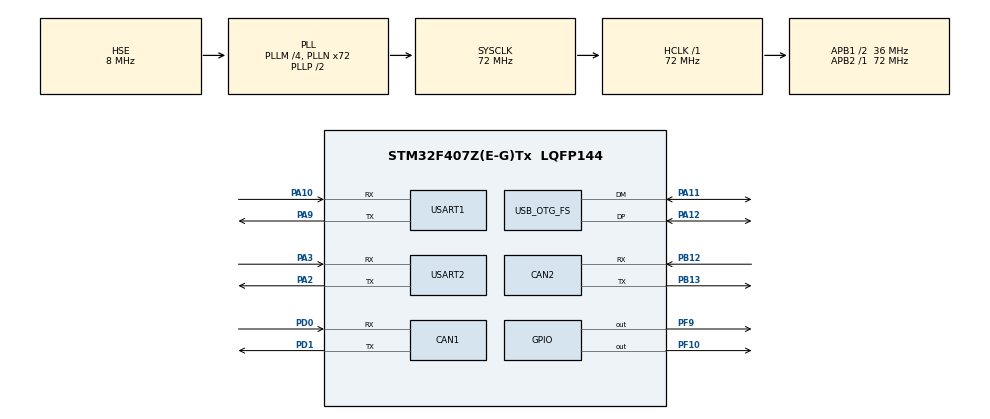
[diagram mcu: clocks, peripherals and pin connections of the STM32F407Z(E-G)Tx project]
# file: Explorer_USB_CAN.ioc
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CAN1.CalculateTimeQuantum=444.44444444444446
CAN2.CalculateTimeQuantum=444.44444444444446
FREERTOS.Tasks01=defaultTask,0,128,StartDefaultTask,Default,NULL
Mcu.Family=STM32F4
Mcu.Name=STM32F407Z(E-G)Tx
Mcu.Package=LQFP144
NVIC.CAN1_RX0_IRQn=true\:5\:0\:false\:false\:true\:true\:true\:true
NVIC.CAN1_RX1_IRQn=true\:5\:0\:false\:false\:true\:true\:true\:true
NVIC.CAN1_SCE_IRQn=true\:5\:0\:false\:false\:true\:true\:true\:true
NVIC.CAN1_TX_IRQn=true\:5\:0\:false\:false\:true\:true\:true\:true
NVIC.CAN2_RX0_IRQn=true\:5\:0\:false\:false\:true\:true\:true\:true
NVIC.CAN2_RX1_IRQn=true\:5\:0\:false\:false\:true\:true\:true\:true
NVIC.CAN2_SCE_IRQn=true\:5\:0\:false\:false\:true\:true\:true\:true
NVIC.CAN2_TX_IRQn=true\:5\:0\:false\:false\:true\:true\:true\:true
NVIC.OTG_FS_IRQn=true\:5\:0\:false\:false\:true\:true\:false\:true
NVIC.PriorityGroup=NVIC_PRIORITYGROUP_4
NVIC.USART1_IRQn=true\:5\:0\:false\:false\:true\:true\:true\:true
NVIC.USART2_IRQn=true\:5\:0\:false\:false\:true\:true\:true\:true
PA10.Mode=Asynchronous
PA10.Signal=USART1_RX
PA11.Mode=Device_Only
PA11.Signal=USB_OTG_FS_DM
PA12.Mode=Device_Only
PA12.Signal=USB_OTG_FS_DP
PA2.Mode=Asynchronous
PA2.Signal=USART2_TX
PA3.Mode=Asynchronous
PA3.Signal=USART2_RX
PA9.Mode=Asynchronous
PA9.Signal=USART1_TX
PB12.Mode=Slave
PB12.Signal=CAN2_RX
PB13.Mode=Slave
PB13.Signal=CAN2_TX
PC14-OSC32_IN.Mode=LSE-External-Oscillator
PC14-OSC32_IN.Signal=RCC_OSC32_IN
PC15-OSC32_OUT.Mode=LSE-External-Oscillator
PC15-OSC32_OUT.Signal=RCC_OSC32_OUT
PD0.Mode=Master
PD0.Signal=CAN1_RX
PD1.Mode=Master
PD1.Signal=CAN1_TX
PF10.Signal=GPIO_Output
PF9.Signal=GPIO_Output
PH0-OSC_IN.Mode=HSE-External-Oscillator
PH0-OSC_IN.Signal=RCC_OSC_IN
PH1-OSC_OUT.Mode=HSE-External-Oscillator
PH1-OSC_OUT.Signal=RCC_OSC_OUT
ProjectManager.HeapSize=0x800
ProjectManager.StackSize=0x800
ProjectManager.TargetToolchain=TrueSTUDIO
RCC.48MHZClocksFreq_Value=48000000
RCC.AHBFreq_Value=72000000
RCC.APB1CLKDivider=RCC_HCLK_DIV2
RCC.APB1Freq_Value=36000000
RCC.APB1TimFreq_Value=72000000
RCC.APB2Freq_Value=72000000
RCC.APB2TimFreq_Value=72000000
RCC.CortexFreq_Value=72000000
RCC.HCLKFreq_Value=72000000
RCC.HSE_VALUE=8000000
RCC.HSI_VALUE=16000000
RCC.PLLM=4
RCC.PLLN=72
RCC.PLLQ=3
RCC.SYSCLKFreq_VALUE=72000000
RCC.SYSCLKSource=RCC_SYSCLKSOURCE_PLLCLK
RCC.VCOOutputFreq_Value=144000000
USART1.VirtualMode=VM_ASYNC
USART2.VirtualMode=VM_ASYNC
USB_DEVICE.CLASS_NAME_FS=CDC
USB_DEVICE.VirtualMode-CDC_FS=Cdc
USB_DEVICE.VirtualModeFS=Cdc_FS
USB_OTG_FS.VirtualMode=Device_Only
VP_FREERTOS_VS_CMSIS_V1.Mode=CMSIS_V1
VP_USB_DEVICE_VS_USB_DEVICE_CDC_FS.Mode=CDC_FS
board=custom

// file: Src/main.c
/* USER CODE BEGIN Header */
/**
  ******************************************************************************
  * @file           : main.c
  * @brief          : Main program body
  ******************************************************************************
  * @attention
  *
  * <h2><center>&copy; Copyright (c) 2019 STMicroelectronics.
  * All rights reserved.</center></h2>
  *
  * This software component is licensed by ST under Ultimate Liberty license
  * SLA0044, the "License"; You may not use this file except in compliance with
  * the License. You may obtain a copy of the License at:
  *                             www.st.com/SLA0044
  *
  ******************************************************************************
  */
/* USER CODE END Header */

#include "main.h"
#include "cmsis_os.h"
#include "can.h"
#include "usart.h"
#include "usb_device.h"
#include "gpio.h"
#include <stdio.h>

void SystemClock_Config(void);
void MX_FREERTOS_Init(void);

int main(void)
{

  /* MCU Configuration--------------------------------------------------------*/

  /* Reset of all peripherals, Initializes the Flash interface and the Systick. */
  HAL_Init();

  /* Configure the system clock */
  SystemClock_Config();

  /* Initialize all configured peripherals */
  MX_GPIO_Init();
  MX_CAN1_Init();
  MX_CAN2_Init();
  MX_USART1_UART_Init();
  MX_USART2_UART_Init();
  /* USER CODE BEGIN 2 */
 printf("%s->%s->%d",__FILE__,__FUNCTION__,__LINE__);
  /* USER CODE END 2 */

  /* Call init function for freertos objects (in freertos.c) */
  MX_FREERTOS_Init();

  /* Start scheduler */
  osKernelStart();

  /* We should never get here as control is now taken by the scheduler */

  /* Infinite loop */
  while (1)
  {

  }
}

void SystemClock_Config(void)
{
  RCC_OscInitTypeDef RCC_OscInitStruct = {0};
  RCC_ClkInitTypeDef RCC_ClkInitStruct = {0};

  /** Configure the main internal regulator output voltage
  */
  __HAL_RCC_PWR_CLK_ENABLE();
  __HAL_PWR_VOLTAGESCALING_CONFIG(PWR_REGULATOR_VOLTAGE_SCALE1);
  /** Initializes the CPU, AHB and APB busses clocks
  */
  RCC_OscInitStruct.OscillatorType = RCC_OSCILLATORTYPE_HSE;
  RCC_OscInitStruct.HSEState = RCC_HSE_ON;
  RCC_OscInitStruct.PLL.PLLState = RCC_PLL_ON;
  RCC_OscInitStruct.PLL.PLLSource = RCC_PLLSOURCE_HSE;
  RCC_OscInitStruct.PLL.PLLM = 4;
  RCC_OscInitStruct.PLL.PLLN = 72;
  RCC_OscInitStruct.PLL.PLLP = RCC_PLLP_DIV2;
  RCC_OscInitStruct.PLL.PLLQ = 3;
  if (HAL_RCC_OscConfig(&RCC_OscInitStruct) != HAL_OK)
  {
    Error_Handler();
  }
  /** Initializes the CPU, AHB and APB busses clocks
  */
  RCC_ClkInitStruct.ClockType = RCC_CLOCKTYPE_HCLK|RCC_CLOCKTYPE_SYSCLK
                              |RCC_CLOCKTYPE_PCLK1|RCC_CLOCKTYPE_PCLK2;
  RCC_ClkInitStruct.SYSCLKSource = RCC_SYSCLKSOURCE_PLLCLK;
  RCC_ClkInitStruct.AHBCLKDivider = RCC_SYSCLK_DIV1;
  RCC_ClkInitStruct.APB1CLKDivider = RCC_HCLK_DIV2;
  RCC_ClkInitStruct.APB2CLKDivider = RCC_HCLK_DIV1;

  if (HAL_RCC_ClockConfig(&RCC_ClkInitStruct, FLASH_LATENCY_2) != HAL_OK)
  {
    Error_Handler();
  }
}

void Error_Handler(void)
{
}

/************************ (C) COPYRIGHT STMicroelectronics *****END OF FILE****/

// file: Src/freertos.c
/* USER CODE BEGIN Header */
/**
 ******************************************************************************
 * File Name          : freertos.c
 * Description        : Code for freertos applications
 ******************************************************************************
 * @attention
 *
 * <h2><center>&copy; Copyright (c) 2019 STMicroelectronics.
 * All rights reserved.</center></h2>
 *
 * This software component is licensed by ST under Ultimate Liberty license
 * SLA0044, the "License"; You may not use this file except in compliance with
 * the License. You may obtain a copy of the License at:
 *                             www.st.com/SLA0044
 *
 ******************************************************************************
 */
/* USER CODE END Header */

#include "FreeRTOS.h"
#include "task.h"
#include "main.h"
#include "cmsis_os.h"
#include <stdio.h>
#include <string.h>

/* USER CODE BEGIN Variables */
extern UART_HandleTypeDef huart2;
/* USER CODE END Variables */
osThreadId defaultTaskHandle;

void StartDefaultTask(void const * argument);

extern void MX_USB_DEVICE_Init(void);
void MX_FREERTOS_Init(void); /* (MISRA C 2004 rule 8.1) */

/* GetIdleTaskMemory prototype (linked to static allocation support) */
void vApplicationGetIdleTaskMemory(StaticTask_t **ppxIdleTaskTCBBuffer,
		StackType_t **ppxIdleTaskStackBuffer, uint32_t *pulIdleTaskStackSize);

/* USER CODE BEGIN GET_IDLE_TASK_MEMORY */
static StaticTask_t xIdleTaskTCBBuffer;
static StackType_t xIdleStack[configMINIMAL_STACK_SIZE];

void vApplicationGetIdleTaskMemory(StaticTask_t **ppxIdleTaskTCBBuffer,
		StackType_t **ppxIdleTaskStackBuffer, uint32_t *pulIdleTaskStackSize) {
	*ppxIdleTaskTCBBuffer = &xIdleTaskTCBBuffer;
	*ppxIdleTaskStackBuffer = &xIdleStack[0];
	*pulIdleTaskStackSize = configMINIMAL_STACK_SIZE;
	/* place for user code */
}
/* USER CODE END GET_IDLE_TASK_MEMORY */

void MX_FREERTOS_Init(void) {

	/* Create the thread(s) */
	/* definition and creation of defaultTask */
	osThreadDef(defaultTask, StartDefaultTask, osPriorityNormal, 0, 128);
	defaultTaskHandle = osThreadCreate(osThread(defaultTask), NULL);

}

void StartDefaultTask(void const * argument) {
	/* init code for USB_DEVICE */
	MX_USB_DEVICE_Init();

	/* USER CODE BEGIN StartDefaultTask */
	/* Infinite loop */
	for (;;) {
		//HAL_UART_Transmit(&huart2, (uint8_t*)"hello world\r\n",strlen("hello world\r\n"), HAL_MAX_DELAY);
		printf("hello world\r\n");
		__io_putchar('A');
		osDelay(1000);
	}
	/* USER CODE END StartDefaultTask */
}

/************************ (C) COPYRIGHT STMicroelectronics *****END OF FILE****/
